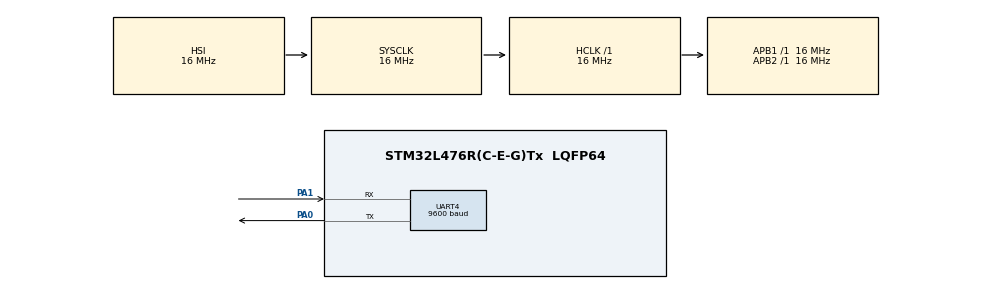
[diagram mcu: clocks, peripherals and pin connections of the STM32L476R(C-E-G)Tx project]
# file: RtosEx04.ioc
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FREERTOS.Mutexes01=myMutex,Dynamic,NULL,Available
FREERTOS.Tasks01=tafera1,24,128,tafera1_fun,Default,NULL,Dynamic,NULL,NULL;tafera2,24,128,tafera2_fun,Default,NULL,Dynamic,NULL,NULL
FREERTOS.configUSE_NEWLIB_REENTRANT=1
Mcu.Family=STM32L4
Mcu.Name=STM32L476R(C-E-G)Tx
Mcu.Package=LQFP64
NVIC.PriorityGroup=NVIC_PRIORITYGROUP_4
NVIC.TIM1_UP_TIM16_IRQn=true\:15\:0\:false\:false\:true\:false\:false\:true\:true
NVIC.TimeBase=TIM1_UP_TIM16_IRQn
NVIC.TimeBaseIP=TIM1
PA0.Mode=Asynchronous
PA0.Signal=UART4_TX
PA1.Mode=Asynchronous
PA1.Signal=UART4_RX
ProjectManager.HeapSize=0x200
ProjectManager.StackSize=0x400
ProjectManager.TargetToolchain=STM32CubeIDE
RCC.ADCFreq_Value=64000000
RCC.AHBFreq_Value=16000000
RCC.APB1Freq_Value=16000000
RCC.APB1TimFreq_Value=16000000
RCC.APB2Freq_Value=16000000
RCC.APB2TimFreq_Value=16000000
RCC.CortexFreq_Value=16000000
RCC.HCLKFreq_Value=16000000
RCC.HSE_VALUE=8000000
RCC.HSI_VALUE=16000000
RCC.MSI_VALUE=4000000
RCC.PLLN=10
RCC.PLLSourceVirtual=RCC_PLLSOURCE_HSI
RCC.PREFETCH_ENABLE=1
RCC.SYSCLKFreq_VALUE=16000000
RCC.SYSCLKSource=RCC_SYSCLKSOURCE_HSI
RCC.USBFreq_Value=64000000
RCC.VCOOutputFreq_Value=160000000
UART4.BaudRate=9600
UART4.Mode=MODE_TX
VP_FREERTOS_VS_CMSIS_V2.Mode=CMSIS_V2
VP_SYS_VS_tim1.Mode=TIM1
board=NUCLEO-L476RG

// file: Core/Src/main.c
/* USER CODE BEGIN Header */
/**
  ******************************************************************************
  * @file           : main.c
  * @brief          : Main program body
  ******************************************************************************
  * @attention
  *
  * Copyright (c) 2025 STMicroelectronics.
  * All rights reserved.
  *
  * This software is licensed under terms that can be found in the LICENSE file
  * in the root directory of this software component.
  * If no LICENSE file comes with this software, it is provided AS-IS.
  *
  ******************************************************************************
  */
/* USER CODE END Header */
#include "main.h"
#include "cmsis_os.h"

UART_HandleTypeDef huart4;

/* Definitions for tafera1 */
osThreadId_t tafera1Handle;
const osThreadAttr_t tafera1_attributes = {
  .name = "tafera1",
  .stack_size = 128 * 4,
  .priority = (osPriority_t) osPriorityNormal,
};
/* Definitions for tafera2 */
osThreadId_t tafera2Handle;
const osThreadAttr_t tafera2_attributes = {
  .name = "tafera2",
  .stack_size = 128 * 4,
  .priority = (osPriority_t) osPriorityNormal,
};
/* Definitions for myMutex */
osMutexId_t myMutexHandle;
const osMutexAttr_t myMutex_attributes = {
  .name = "myMutex"
};

void SystemClock_Config(void);
static void MX_GPIO_Init(void);
static void MX_UART4_Init(void);
void tafera1_fun(void *argument);
void tafera2_fun(void *argument);

int main(void)
{

  /* MCU Configuration--------------------------------------------------------*/

  /* Reset of all peripherals, Initializes the Flash interface and the Systick. */
  HAL_Init();

  /* Configure the system clock */
  SystemClock_Config();

  /* Initialize all configured peripherals */
  MX_GPIO_Init();
  MX_UART4_Init();

  /* Init scheduler */
  osKernelInitialize();
  /* Create the mutex(es) */
  /* creation of myMutex */
  myMutexHandle = osMutexNew(&myMutex_attributes);

  /* Create the thread(s) */
  /* creation of tafera1 */
  tafera1Handle = osThreadNew(tafera1_fun, NULL, &tafera1_attributes);

  /* creation of tafera2 */
  tafera2Handle = osThreadNew(tafera2_fun, NULL, &tafera2_attributes);

  /* Start scheduler */
  osKernelStart();

  /* We should never get here as control is now taken by the scheduler */

  /* Infinite loop */
  while (1)
  {

  }
}

void SystemClock_Config(void)
{
  RCC_OscInitTypeDef RCC_OscInitStruct = {0};
  RCC_ClkInitTypeDef RCC_ClkInitStruct = {0};

  /** Configure the main internal regulator output voltage
  */
  if (HAL_PWREx_ControlVoltageScaling(PWR_REGULATOR_VOLTAGE_SCALE1) != HAL_OK)
  {
    Error_Handler();
  }

  /** Initializes the RCC Oscillators according to the specified parameters
  * in the RCC_OscInitTypeDef structure.
  */
  RCC_OscInitStruct.OscillatorType = RCC_OSCILLATORTYPE_HSI;
  RCC_OscInitStruct.HSIState = RCC_HSI_ON;
  RCC_OscInitStruct.HSICalibrationValue = RCC_HSICALIBRATION_DEFAULT;
  RCC_OscInitStruct.PLL.PLLState = RCC_PLL_NONE;
  if (HAL_RCC_OscConfig(&RCC_OscInitStruct) != HAL_OK)
  {
    Error_Handler();
  }

  /** Initializes the CPU, AHB and APB buses clocks
  */
  RCC_ClkInitStruct.ClockType = RCC_CLOCKTYPE_HCLK|RCC_CLOCKTYPE_SYSCLK
                              |RCC_CLOCKTYPE_PCLK1|RCC_CLOCKTYPE_PCLK2;
  RCC_ClkInitStruct.SYSCLKSource = RCC_SYSCLKSOURCE_HSI;
  RCC_ClkInitStruct.AHBCLKDivider = RCC_SYSCLK_DIV1;
  RCC_ClkInitStruct.APB1CLKDivider = RCC_HCLK_DIV1;
  RCC_ClkInitStruct.APB2CLKDivider = RCC_HCLK_DIV1;

  if (HAL_RCC_ClockConfig(&RCC_ClkInitStruct, FLASH_LATENCY_0) != HAL_OK)
  {
    Error_Handler();
  }
}

static void MX_UART4_Init(void)
{

  huart4.Instance = UART4;
  huart4.Init.BaudRate = 9600;
  huart4.Init.WordLength = UART_WORDLENGTH_8B;
  huart4.Init.StopBits = UART_STOPBITS_1;
  huart4.Init.Parity = UART_PARITY_NONE;
  huart4.Init.Mode = UART_MODE_TX;
  huart4.Init.HwFlowCtl = UART_HWCONTROL_NONE;
  huart4.Init.OverSampling = UART_OVERSAMPLING_16;
  huart4.Init.OneBitSampling = UART_ONE_BIT_SAMPLE_DISABLE;
  huart4.AdvancedInit.AdvFeatureInit = UART_ADVFEATURE_NO_INIT;
  if (HAL_UART_Init(&huart4) != HAL_OK)
  {
    Error_Handler();
  }

}

static void MX_GPIO_Init(void)
{

  /* GPIO Ports Clock Enable */
  __HAL_RCC_GPIOA_CLK_ENABLE();

}

void tafera1_fun(void *argument)
{
  /* USER CODE BEGIN 5 */
  /* Infinite loop */
  for(;;)
  {
    osDelay(1000);
    osMutexAcquire(myMutexHandle, 1000); // requisitando recurso
    HAL_UART_Transmit(&huart4, "t1\r\n", 4, 100);
    osMutexRelease(myMutexHandle); // liberando
  }
  /* USER CODE END 5 */
}

void tafera2_fun(void *argument)
{
  /* USER CODE BEGIN tafera2_fun */
  /* Infinite loop */
  for(;;)
  {
	  osDelay(1000);
	  osMutexAcquire(myMutexHandle, 1000); // requisitando recurso
	  HAL_UART_Transmit(&huart4, "t2\r\n", 4, 100);
	  osMutexRelease(myMutexHandle); // liberando
  }
  /* USER CODE END tafera2_fun */
}

void HAL_TIM_PeriodElapsedCallback(TIM_HandleTypeDef *htim)
{
  if (htim->Instance == TIM1) {
    HAL_IncTick();
  }
}

void Error_Handler(void)
{
  __disable_irq();
  while (1)
  {
  }
}
